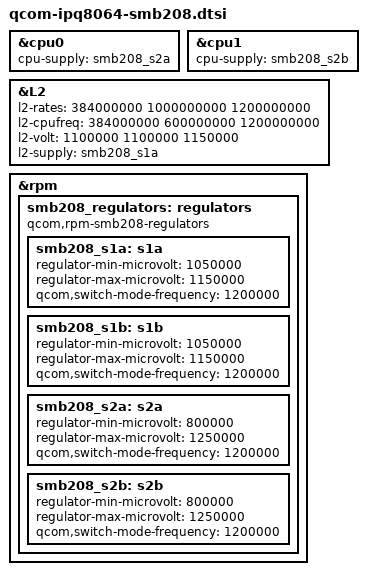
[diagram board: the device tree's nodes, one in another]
// SPDX-License-Identifier: GPL-2.0

#include "qcom-ipq8064.dtsi"

&cpu0 {
	cpu-supply = <&smb208_s2a>;
};

&cpu1 {
	cpu-supply = <&smb208_s2b>;
};

&L2 {
	l2-rates = <384000000 1000000000 1200000000>;
	l2-cpufreq = <384000000 600000000 1200000000>;
	l2-volt = <1100000 1100000 1150000>;
	l2-supply = <&smb208_s1a>;
};

&rpm {
	smb208_regulators: regulators {
		compatible = "qcom,rpm-smb208-regulators";

		smb208_s1a: s1a {
			regulator-min-microvolt = <1050000>;
			regulator-max-microvolt = <1150000>;

			qcom,switch-mode-frequency = <1200000>;
		};

		smb208_s1b: s1b {
			regulator-min-microvolt = <1050000>;
			regulator-max-microvolt = <1150000>;

			qcom,switch-mode-frequency = <1200000>;
		};

		smb208_s2a: s2a {
			regulator-min-microvolt = < 800000>;
			regulator-max-microvolt = <1250000>;

			qcom,switch-mode-frequency = <1200000>;
		};

		smb208_s2b: s2b {
			regulator-min-microvolt = < 800000>;
			regulator-max-microvolt = <1250000>;

			qcom,switch-mode-frequency = <1200000>;
		};
	};
};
